AUTOSAR XML (schema 4-0-3)
package /DemoApplication/ImplementationDataTypes
  impl type ComM_ModeType: compu {0=NO_COMMUNICATION, 1=SILENT_COMMUNICATION, 2=FULL_COMMUNICATION}, implementation-data-type=uint8
package /DemoApplication/ConstantSpecifications
  constant specification CONST_0c0f918b8f394b8586f853bd5: value-spec=CONST_0c0f918b8f394b8586f853bd5:0
  constant specification CONST_951406b330e947ed9394eb477: value-spec=CONST_951406b330e947ed9394eb477:0
package /DemoApplication/PortInterfaces
  client server interface If_CounterModify
    operation SetCounterAndAdd
      arg newCounterValue: type=uint8, direction=IN
      arg returnSum: type=uint8, direction=OUT
  client server interface If_DiscreteValueOutput
    operation SetDiscreteValue
      arg value: type=uint32, direction=IN
  sender receiver interface If_Counter
    data CounterValue: type=uint8, init-value=CONST_951406b330e947ed9394eb477:0
  client server interface DETService: is-service=true
    operation ReportError: possible-error=E_OK
      arg InstanceId: type=uint8, direction=IN
      arg ApiId: type=uint8, direction=IN
      arg ErrorId: type=uint8, direction=IN
    error E_OK: error-code=0
  client server interface NvMService: is-service=true
    operation SetRamBlockStatus: possible-error=NvMService/E_NOT_OK
      arg BlockChanged: type=boolean, direction=IN
    error E_NOT_OK: error-code=1
  client server interface ComM_UserRequest: is-service=true
    operation RequestComMode: possible-error=[ComM_UserRequest/E_NOT_OK, E_MODE_LIMITATION]
      arg ComMode: type=ComM_ModeType, direction=IN
    error E_NOT_OK: error-code=1
    error E_MODE_LIMITATION: error-code=2
  sender receiver interface If_Internal
    data EventMessage: sw-impl-policy=QUEUED, type=uint8
package /DemoApplication/SwComponentTypes
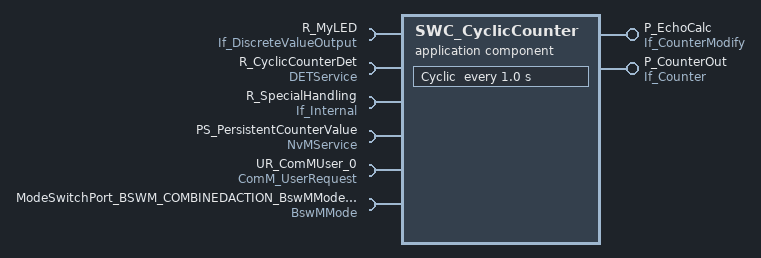
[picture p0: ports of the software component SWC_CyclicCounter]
  application sw component type SWC_CyclicCounter
    provide port P_EchoCalc: server-com-spec{operation=SetCounterAndAdd, queue-length=1}, provided-interface=If_CounterModify
    provide port P_CounterOut: nonqueued-sender-com-spec{data-element=CounterValue, init-value=0}, provided-interface=If_Counter
    6 x require port:
      R_MyLED: required-interface=If_DiscreteValueOutput
      R_CyclicCounterDet: required-interface=DETService
      R_SpecialHandling: queued-receiver-com-spec{data-element=EventMessage, queue-length=8}, required-interface=If_Internal
      PS_PersistentCounterValue: required-interface=NvMService
      UR_ComMUser_0: required-interface=ComM_UserRequest
      ModeSwitchPort_BSWM_COMBINEDACTION_BswMMode_PortInterfaces_BswMMode: required-interface=BswMMode
    behavior IB_SWC_CyclicCounter: data-type-mapping=BswMModeMapping, handle-termination-and-restart=NO-SUPPORT
      timing event CyclicEvent: start-on-event=Cyclic, period=1.0
        disabled-mode:
          ModeSwitchPort_BSWM_COMBINEDACTION_BswMMode_PortInterfaces_BswMMode.CurrentMode.EB_INTGR_BSWM_STARTUP_TWO_A
          ModeSwitchPort_BSWM_COMBINEDACTION_BswMMode_PortInterfaces_BswMMode.CurrentMode.EB_INTGR_BSWM_STARTUP_TWO_B
          ModeSwitchPort_BSWM_COMBINEDACTION_BswMMode_PortInterfaces_BswMMode.CurrentMode.EB_INTGR_BSWM_GO_OFF_ONE_A
          ModeSwitchPort_BSWM_COMBINEDACTION_BswMMode_PortInterfaces_BswMMode.CurrentMode.EB_INTGR_BSWM_GO_OFF_ONE_B
          ModeSwitchPort_BSWM_COMBINEDACTION_BswMMode_PortInterfaces_BswMMode.CurrentMode.EB_INTGR_BSWM_WAKEUP_TWO
          ModeSwitchPort_BSWM_COMBINEDACTION_BswMMode_PortInterfaces_BswMMode.CurrentMode.EB_INTGR_BSWM_PRP_SHUTDOWN
      swc mode switch event ModeSwitchedRunTwo: start-on-event=Init, activation=ON-ENTRY, mode=ModeSwitchPort_BSWM_COMBINEDACTION_BswMMode_PortInterfaces_BswMMode.CurrentMode.EB_INTGR_BSWM_RUN_TWO
      swc mode switch event ModeSwitchedPrpShutdown: start-on-event=Shutdown, activation=ON-ENTRY, mode=ModeSwitchPort_BSWM_COMBINEDACTION_BswMMode_PortInterfaces_BswMMode.CurrentMode.EB_INTGR_BSWM_PRP_SHUTDOWN
      operation invoked event SetCounterOperationInvoked: start-on-event=SetCounter, operation=P_EchoCalc.SetCounterAndAdd
      explicit-inter-runnable-variables:
        data CurrentCounterValue: type=uint8, init-value=0
      per instance memory PimCounterValue: init-value=99, type=CounterValueType, type-definition=uint8
      per-instance-parameters:
        parameter data prototype PrmCounterValue: type=uint8, init-value=99
      port-api-options:
        enable-take-address=false, indirect-api=false, port=P_EchoCalc
        enable-take-address=false, indirect-api=false, port=SWC_CyclicCounter/P_CounterOut
      4 x runnable:
        SetCounter: can-be-invoked-concurrently=true, symbol=SWC_CyclicCounter_SetCounter
          read-local-variables:
            access CurrentCounterValue1: accessed-variable=CurrentCounterValue
          written-local-variables:
            access CurrentCounterValue2: accessed-variable=CurrentCounterValue
        Cyclic: symbol=SWC_CyclicCounter_Cyclic
          data-receive-point-by-arguments:
            access DRP_P_Special_EventMessage: accessed-variable=R_SpecialHandling.EventMessage
          data-send-points:
            access DWA_P_CounterOut_CounterValue: accessed-variable=P_CounterOut.CounterValue
          read-local-variables:
            access CurrentCounterValue3: accessed-variable=CurrentCounterValue
          sync call CS_EchoResult_SetCounterAndAdd: operation=R_MyLED.SetDiscreteValue, timeout=0
          sync call CS_DETService_ReportError: operation=R_CyclicCounterDet.ReportError, timeout=0
          sync call CS_UR_ComMUser_0_ComM_UserRequest: operation=UR_ComMUser_0.RequestComMode, timeout=0
          written-local-variables:
            access CurrentCounterValue4: accessed-variable=CurrentCounterValue
        Init: symbol=SWC_CyclicCounter_Init
          parameter access PA_PersistentCounterValue: accessed-parameter=PrmCounterValue
          sync call CS_UR_ComMUser_0_ComM_UserRequest: operation=UR_ComMUser_0.RequestComMode, timeout=0
          written-local-variables:
            access CurrentCounterValue: accessed-variable=CurrentCounterValue
        Shutdown: symbol=SWC_CyclicCounter_Shutdown
          read-local-variables:
            access CurrentCounterValue3: accessed-variable=CurrentCounterValue
          sync call CS_NvMService_SetRamBlockStatus: operation=PS_PersistentCounterValue.SetRamBlockStatus, timeout=0
      swc service dependency ServiceDependency: assigned-ports=role-based-port-assignment={port-prototype=PS_PersistentCounterValue, role=NvMService}
        assigned-datas:
          role=ramMirror, used-pim=PimCounterValue
          role=defaultValue, used-parameter-element=PrmCounterValue
        service-needs:
          nv block needs PersistentCounterValue: calc-ram-block-crc=false, check-static-block-id=false, n-data-sets=1, n-rom-blocks=1, readonly=false, reliability=NO-PROTECTION, resistant-to-changed-sw=false, restore-at-start=true, store-at-shutdown=true, write-only-once=false, write-verification=false, writing-priority=MEDIUM
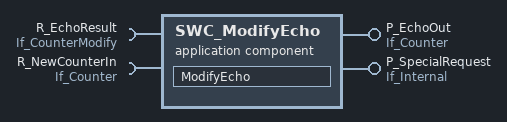
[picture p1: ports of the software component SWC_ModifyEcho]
  application sw component type SWC_ModifyEcho
    require port R_EchoResult: required-interface=If_CounterModify
    require port R_NewCounterIn: nonqueued-receiver-com-spec{data-element=CounterValue, init-value=constant-reference=CONST_0c0f918b8f394b8586f853bd5}, required-interface=If_Counter
    provide port P_EchoOut: nonqueued-sender-com-spec{data-element=CounterValue, init-value=0}, provided-interface=If_Counter
    provide port P_SpecialRequest: provided-interface=If_Internal
    behavior IB_SWC_ModifyEcho: handle-termination-and-restart=NO-SUPPORT
      data received event DataReceivedEvent: start-on-event=ModifyEcho, data=R_NewCounterIn.CounterValue
      port-api-options:
        enable-take-address=false, indirect-api=false, port=R_EchoResult
        enable-take-address=false, indirect-api=false, port=R_NewCounterIn
        enable-take-address=false, indirect-api=false, port=P_EchoOut
      runnable ModifyEcho: symbol=SWC_ModifyEcho_ModifyEcho
        data-receive-point-by-arguments:
          access DRP_R_NewCounterIn_CounterValue: accessed-variable=R_NewCounterIn.CounterValue
        data-send-points:
          access DSP_P_Special_EventMessage: accessed-variable=P_SpecialRequest.EventMessage
        data-write-access:
          access DWA_P_EchoOut_CounterValue: accessed-variable=P_EchoOut.CounterValue
        sync call CS_EchoResult_SetCounterAndAdd: operation=R_EchoResult.SetCounterAndAdd, timeout=0
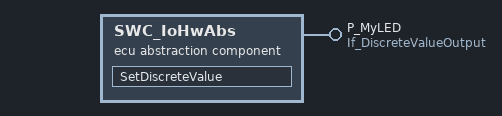
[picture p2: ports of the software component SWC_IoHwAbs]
  ecu abstraction sw component type SWC_IoHwAbs
    provide port P_MyLED: server-com-spec{operation=SetDiscreteValue, queue-length=1}, provided-interface=If_DiscreteValueOutput
    behavior IB_SWC_IoHwAbs: handle-termination-and-restart=NO-SUPPORT, port-api-option{enable-take-address=false, indirect-api=false, port-defined-argument-value{value=0, value-type=uint32}, port=P_MyLED}
      operation invoked event SetDiscreteValueOperationInvoked: start-on-event=SetDiscreteValue, operation=P_MyLED.SetDiscreteValue
      runnable SetDiscreteValue: can-be-invoked-concurrently=true, symbol=SWC_IoHwAbs_SetDiscreteValue
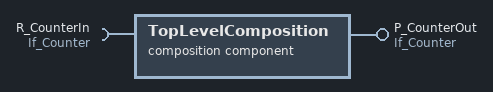
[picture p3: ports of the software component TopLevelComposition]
  composition sw component type TopLevelComposition
    provide port P_CounterOut: provided-interface=If_Counter
    require port R_CounterIn: required-interface=If_Counter
    component SWC_ModifyEcho: type=SWC_ModifyEcho
    component SWC_CyclicCounter: type=SWC_CyclicCounter
    component SWC_IoHwAbs: type=SWC_IoHwAbs
    delegate SWC_ModifyEcho.R_NewCounterIn <-> outer port R_CounterIn
    delegate SWC_ModifyEcho.P_EchoOut <-> outer port TopLevelComposition/P_CounterOut
    delegate SWC_CyclicCounter.P_CounterOut <-> outer port TopLevelComposition/P_CounterOut
    connect SWC_CyclicCounter.P_EchoCalc -> SWC_ModifyEcho.R_EchoResult
    connect SWC_ModifyEcho.P_SpecialRequest -> SWC_CyclicCounter.R_SpecialHandling
    connect SWC_IoHwAbs.P_MyLED -> SWC_CyclicCounter.R_MyLED
package /DemoApplication/SwcImplementations
  swc implementation Impl_SWC_CyclicCounter: programming-language=C, sw-version=1.0.0, vendor-id=1, behavior=IB_SWC_CyclicCounter
    code-descriptors:
      code SRC: artifact-descriptors=autosar-engineering-object={short-label=EngObject, category=SWSRC}
    resource consumption Resources
      memory section CODE: sw-addrmethod=CODE
  swc implementation Impl_SWC_ModifyEcho: programming-language=C, sw-version=1.0.0, vendor-id=1, behavior=IB_SWC_ModifyEcho
    code-descriptors:
      code SRC: artifact-descriptors=autosar-engineering-object={short-label=EngObject, category=SWSRC}
    resource consumption Resources
      memory section CODE: sw-addrmethod=CODE
  swc implementation Impl_SWC_IoHwAbs: programming-language=C, sw-version=1.0.0, vendor-id=1, behavior=IB_SWC_IoHwAbs
    code-descriptors:
      code SRC: artifact-descriptors=autosar-engineering-object={short-label=EngObject, category=SWSRC}
    resource consumption Resources
      memory section CODE: sw-addrmethod=CODE
      memory section VAR_UNSPECIFIED: alignment=UNSPECIFIED, sw-addrmethod=VAR
